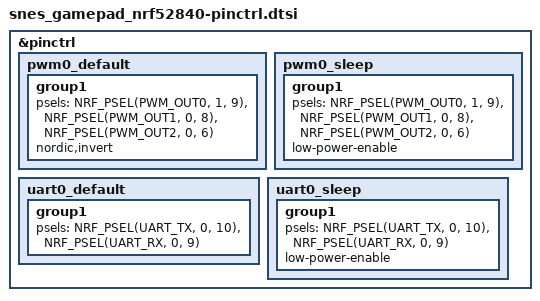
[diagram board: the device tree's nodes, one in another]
/*
 * Copyright (c) 2022 Nordic Semiconductor
 * SPDX-License-Identifier: Apache-2.0
 */

&pinctrl {
	pwm0_default: pwm0_default {
		group1 {
			psels = <NRF_PSEL(PWM_OUT0, 1, 9)>,
			        <NRF_PSEL(PWM_OUT1, 0, 8)>,
			        <NRF_PSEL(PWM_OUT2, 0, 6)>;
			nordic,invert;
		};
	};

	pwm0_sleep: pwm0_sleep {
		group1 {
			psels = <NRF_PSEL(PWM_OUT0, 1, 9)>,
			        <NRF_PSEL(PWM_OUT1, 0, 8)>,
			        <NRF_PSEL(PWM_OUT2, 0, 6)>;
			low-power-enable;
		};
	};

	uart0_default: uart0_default {
		group1 {
			psels = <NRF_PSEL(UART_TX, 0, 10)>,
					<NRF_PSEL(UART_RX, 0, 9)>;
		};
	};

	uart0_sleep: uart0_sleep {
		group1 {
			psels = <NRF_PSEL(UART_TX, 0, 10)>,
					<NRF_PSEL(UART_RX, 0, 9)>;
			low-power-enable;
		};
	};
};
